# ESP32-S31 register map
Vendor: ESPRESSIF SYSTEMS (SHANGHAI) CO., LTD.; Series: ESP32 S-Series; File version: 1
CPU: RV32IMAFC r0p0, little endian, no MPU, FPU, 0 interrupt priority bits
Address unit: 32 bits
Registers are 32-bit, read-write, reset 0x0 unless marked. A register's access mark holds for its fields unless they carry their own. Offsets are from the block's base; [hi:lo] are bit positions.

## DAC — DAC Peripheral
Base 0x2081A000
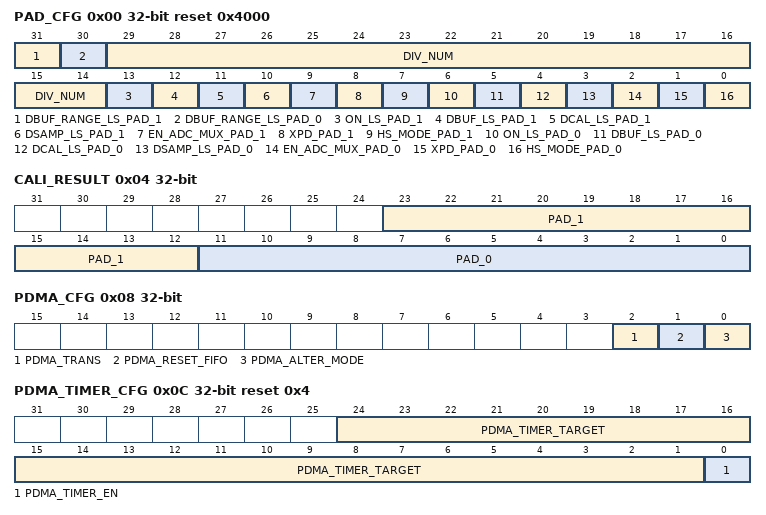
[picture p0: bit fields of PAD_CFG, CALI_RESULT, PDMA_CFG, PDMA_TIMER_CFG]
0x00 PAD_CFG reset 0x4000 — configure dac pad register
  [31] DBUF_RANGE_LS_PAD_1 — 1:when buffer is activated, allow using full code of maximum bitwidth 0:when buffer is not activated, should always be 0
  [30] DBUF_RANGE_LS_PAD_0 — 1:when buffer is activated, allow using full code of maximum bitwidth 0:when buffer is not activated, should always be 0
  [29:14] DIV_NUM — divide number between clk ls and clk hs
  [13] ON_LS_PAD_1 — 1 to turn on the DAC PAD 1 during sample and hold mode
  [12] DBUF_LS_PAD_1 — 1 to turn on the buffer of DAC PAD 1
  [11] DCAL_LS_PAD_1 — 1 to Calibrate the buffer of DAC PAD 1 (DBUF of pad 1 must be 1 during this operation)
  [10] DSAMP_LS_PAD_1 — 1 to start sample and hold mode for DAC PAD 1
  [9] EN_ADC_MUX_PAD_1 — 1 to enable adc mux for DAC PAD 1
  [8] XPD_PAD_1 — 1 to power on DAC PAD 1
  [7] HS_MODE_PAD_1 — 1 to let DAC PAD 1 enter High speed mode
  [6] ON_LS_PAD_0 — 1 to turn on the DAC PAD 0 during sample and hold mode
  [5] DBUF_LS_PAD_0 — 1 to turn on the buffer of DAC PAD 0
  [4] DCAL_LS_PAD_0 — 1 to Calibrate the buffer of DAC PAD 0 (DBUF of pad 1 must be 1 during this operation)
  [3] DSAMP_LS_PAD_0 — 1 to start sample and hold mode for DAC PAD 0
  [2] EN_ADC_MUX_PAD_0 — 1 to enable adc mux for DAC PAD 0
  [1] XPD_PAD_0 — 1 to power on DAC PAD 0
  [0] HS_MODE_PAD_0 — 1 to let DAC PAD 0 enter High speed mode
0x04 CALI_RESULT — DAC CALI result register
  [23:12] PAD_1 — cali result register for pad 1 output
  [11:0] PAD_0 — cali result register for pad 0 output
0x08 PDMA_CFG access per field — dac cfg register
  [2] PDMA_TRANS rw — 1:start transaction for pdma path output 0:stop transaction for pdma path output
  [1] PDMA_RESET_FIFO wo — 1:reset dac fifo 0:no change
  [0] PDMA_ALTER_MODE rw — 1:make rotation between two pads when outputting data of ppdma input path requires reg_dac_1/0_data_sel = 1 0:no change
0x0C PDMA_TIMER_CFG reset 0x4 — PDMA path timer register
  [24:1] PDMA_TIMER_TARGET — dac pdma timer wait target
  [0] PDMA_TIMER_EN — 1:enables using dac timer to reduce output frequency 0:no data output
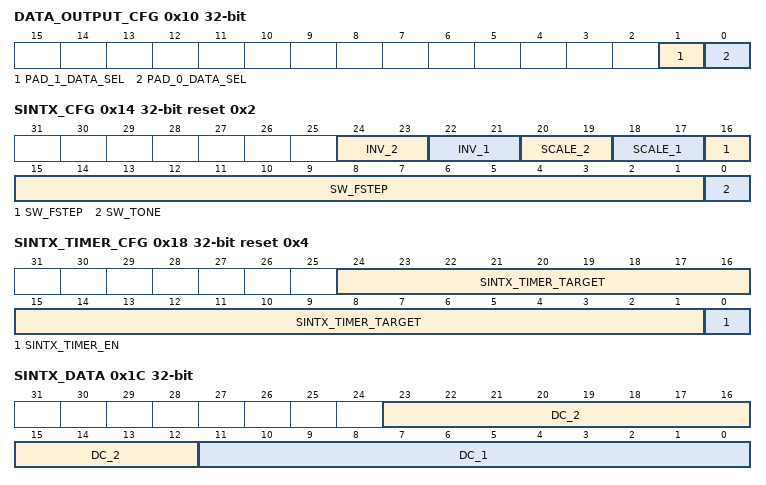
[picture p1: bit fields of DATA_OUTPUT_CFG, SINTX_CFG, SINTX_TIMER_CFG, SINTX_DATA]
0x10 DATA_OUTPUT_CFG — dac DATA OUTPUT cfg register
  [1] PAD_1_DATA_SEL — 1:output pdma data 0:output sintx data
  [0] PAD_0_DATA_SEL — 1:output pdma data 0:output sintx data
0x14 SINTX_CFG reset 0x2 — dac rstn register
  [24:23] INV_2 — bit 1: invert the highest bit of output for pad 1 Bit 0: invert the entire output for pad 1
  [22:21] INV_1 — bit 1: invert the highest bit of output for pad 0 Bit 0: invert the entire output for pad 0
  [20:19] SCALE_2 — software adjust angle velocity foot step for sintx LUT input
  [18:17] SCALE_1 — right shift scaling config for LUT output of sintx for pad 0
  [16:1] SW_FSTEP — software adjust angle velocity foot step for sintx LUT input
  [0] SW_TONE — 1:enable software adjusting current sintx output data 0:disable software adjustment
0x18 SINTX_TIMER_CFG reset 0x4 — SINTX path timer register
  [24:1] SINTX_TIMER_TARGET — dac sintx timer wait target
  [0] SINTX_TIMER_EN — 1:enables using dac timer to reduce output frequency 0:no data output
0x1C SINTX_DATA — dac output register for sintx path
  [23:12] DC_2 — the data output for DAC PAD1 for sintx path
  [11:0] DC_1 — the data output for DAC PAD0 for sintx path
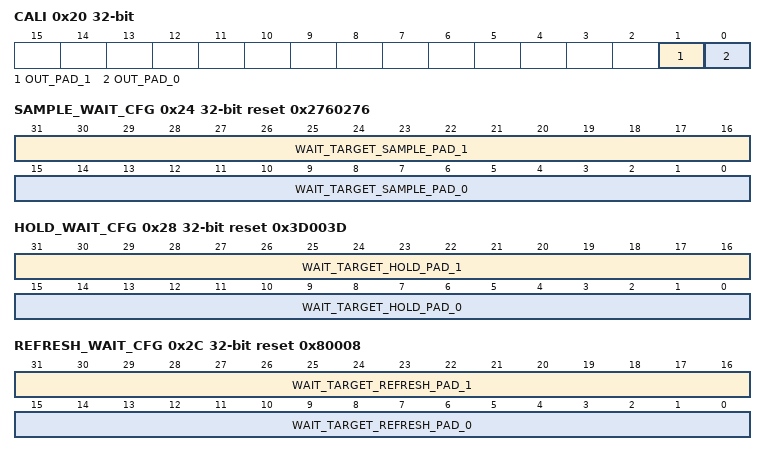
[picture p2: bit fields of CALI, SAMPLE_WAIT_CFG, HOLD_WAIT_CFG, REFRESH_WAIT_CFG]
0x20 CALI ro — cali algorithm register for DAC
  [1] OUT_PAD_1 — cali out from DAC PAD 1
  [0] OUT_PAD_0 — cali out from DAC PAD 0
0x24 SAMPLE_WAIT_CFG reset 0x2760276 — cali sample phase duration register
  [31:16] WAIT_TARGET_SAMPLE_PAD_1 — sample wait target for DAC PAD 0
  [15:0] WAIT_TARGET_SAMPLE_PAD_0 — sample wait target for DAC PAD 1
0x28 HOLD_WAIT_CFG reset 0x3D003D — cali hold phase duration register
  [31:16] WAIT_TARGET_HOLD_PAD_1 — hold wait target for DAC PAD 1
  [15:0] WAIT_TARGET_HOLD_PAD_0 — hold wait target for DAC PAD 0
0x2C REFRESH_WAIT_CFG reset 0x80008 — cali refresh phase duration register
  [31:16] WAIT_TARGET_REFRESH_PAD_1 — refresh wait target for DAC PAD 1
  [15:0] WAIT_TARGET_REFRESH_PAD_0 — refresh wait target for DAC PAD 0
0x30 PDMA_INT_RAW — need_des
  [31] PDMA_EMPTY_INT_RAW
0x34 INT_ST ro — need_des
  [31] PDMA_EMPTY_INT_ST
0x38 INT_ENA — need_des
  [31] PDMA_EMPTY_INT_ENA
0x3C INT_CLR wo — need_des
  [31] PDMA_EMPTY_INT_CLR
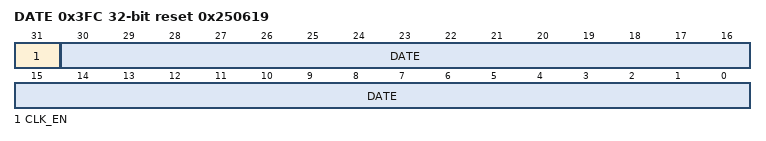
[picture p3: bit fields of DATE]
0x3FC DATE reset 0x250619 — need_des
  [31] CLK_EN — need_des
  [30:0] DATE — need_des
